# 3061MNNIC8 register map
File version: 1.0
Registers are 32-bit, access per field, reset 0x0 unless marked. A register's access mark holds for its fields unless they carry their own. Offsets are from the block's base; [hi:lo] are bit positions.

## CRC — CRC peripheral interface
Base 0x14800000
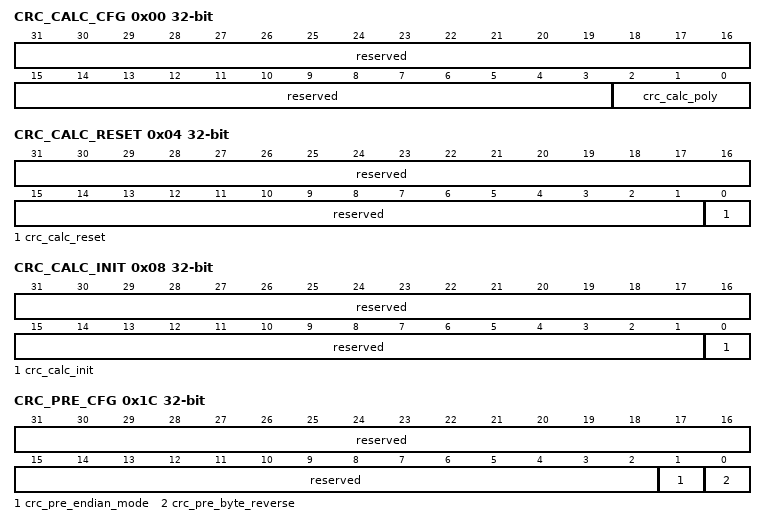
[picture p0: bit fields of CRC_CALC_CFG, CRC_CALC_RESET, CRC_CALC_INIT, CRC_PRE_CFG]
0x00 CRC_CALC_CFG — CRC计算模块，配置寄存器。
  [31:3] reserved ro — 保留。
  [2:0] crc_calc_poly rw — CRC计算模块，多项式配置： 000：CRC-8，多项式0x07； 001：保留； 010：CRC-16，多项式0x8005； 011：CRC-16，多项式0x1021； 100：CRC-32，多项式0x04c11db7； 其他：保留。
0x04 CRC_CALC_RESET — CRC计算模块软复位寄存器,复位计算，不复位配置。
  [31:1] reserved ro — 保留。
  [0] crc_calc_reset rw write-1-clears — CRC计算模块软复位，该位域写1自动清零。复位CRC计算，不复位配置。
0x08 CRC_CALC_INIT — CRC计算模块，初始化寄存器。
  [31:1] reserved ro — 保留。
  [0] crc_calc_init rw write-1-clears — CRC初始值加载信号，该位域写1自动清零，CRC计算初始化。 软件写入该位域，CRC计算初始化完成后，CRC从CRC初始值（crc_calc_init_value位域）开始计算。 注意：软件配置该位域后，再写入crc_data_in位域开始计算。
0x0C CRC_POST_XOR_VALUE rw — CRC后级处理，异或值寄存器。
  [31:0] crc_post_xor_value — CRC后级处理，异或值（XOR）。
0x10 CRC_CALC_INIT_VALUE rw — CRC计算模块，初始值寄存器。
  [31:0] crc_calc_init_value — CRC计算模块，初始值。
0x14 CRC_DATA_IN rw — CRC输入数据寄存器。
  [31:0] crc_data_in — 数据。软件写入需要计算的数据。
0x18 CRC_OUT ro — CRC结果寄存器。
  [31:0] crc_out — CRC结果，超过CRC多项式宽度的比特位是0。
0x1C CRC_PRE_CFG — CRC前级处理，配置寄存器。
  [31:2] reserved ro — 保留。
  [1] crc_pre_endian_mode rw — crc_data_in数据大小端： 0：小端； 1：大端。
  [0] crc_pre_byte_reverse rw — crc_data_in数据在字节内，按位反序（RefIn）： 0：不反序； 1：反序。
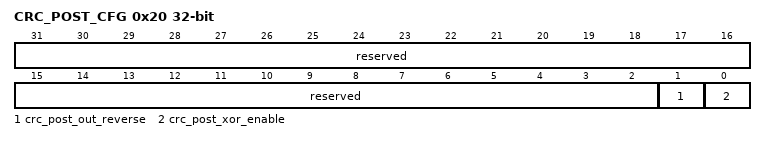
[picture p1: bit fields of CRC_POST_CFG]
0x20 CRC_POST_CFG — CRC后级处理，配置寄存器。
  [31:2] reserved ro — 保留。
  [1] crc_post_out_reverse rw — CRC结果在多项式宽度内，按位反序（RefOut）： 0：不反序； 1：反序。
  [0] crc_post_xor_enable rw — CRC结果异或（XOR）： 0：不异或； 1：异或。

## DAC — DAC peripheral interface
Base 0x18400000
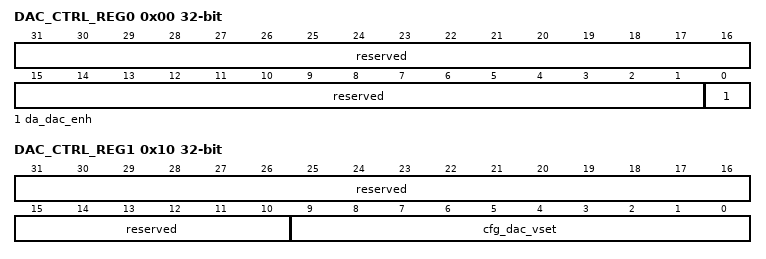
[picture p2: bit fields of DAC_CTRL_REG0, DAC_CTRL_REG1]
0x00 DAC_CTRL_REG0 — DAC控制寄存器0。
  [31:1] reserved ro — 保留。
  [0] da_dac_enh rw — DAC使能信号： 0:关闭; 1:使能。
0x10 DAC_CTRL_REG1 — DAC控制寄存器1。
  [31:10] reserved ro — 保留。
  [9:0] cfg_dac_vset rw — DAC电压档位。

## FLASH_RGN0_SHADOWS — FLASH_RGN0_SHADOWS peripheral interface
Base 0x14720000
0x00 DIE_ID_0 ro — 芯片出厂DIE_ID_0，DIE_ID寄存器。
  [31:0] die_id_0 — 芯片出厂DIE_ID_0，每颗芯片具有特异值。
0x04 DIE_ID_1 ro — 芯片出厂DIE_ID_1，DIE_ID寄存器。
  [31:0] die_id_1 — 芯片出厂DIE_ID_1，每颗芯片具有特异值。
0x10 DIE_ID_2 ro — 芯片出厂DIE_ID_2，DIE_ID寄存器。
  [31:0] die_id_2 — 芯片出厂DIE_ID_2，每颗芯片具有特异值。
0x14 DIE_ID_3 ro — 芯片出厂DIE_ID_3，DIE_ID寄存器。
  [31:0] die_id_3 — 芯片出厂DIE_ID_3，每颗芯片具有特异值。
0x20 CHIP_ID ro — 芯片出厂CHIP_ID，DIE_ID寄存器。
  [31:0] chip_id — 芯片出厂CHIP_ID，每颗芯片具有特异值。

## FLASH_RGN1_SHADOWS — FLASH_RGN1_SHADOWS peripheral interface
Base 0x14720000
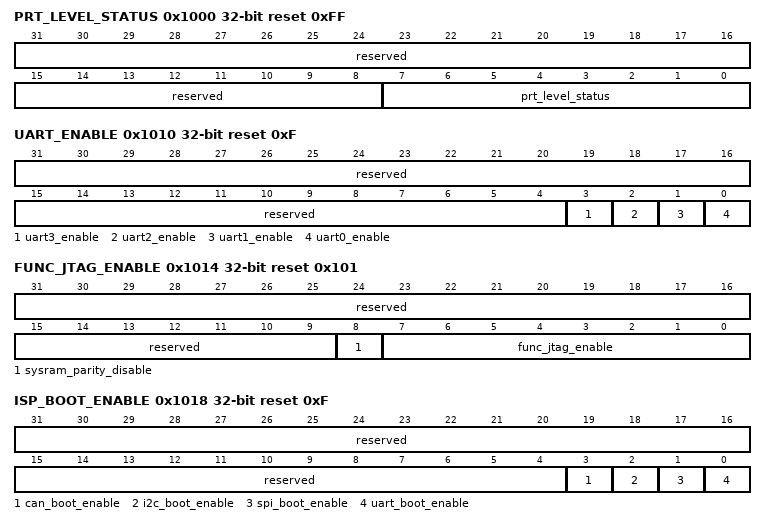
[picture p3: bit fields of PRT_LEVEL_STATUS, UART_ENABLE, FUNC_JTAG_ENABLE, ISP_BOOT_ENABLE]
0x1000 PRT_LEVEL_STATUS ro reset 0xFF — protection level管理标志。
  [31:8] reserved — 保留。
  [7:0] prt_level_status — protection level管理标志。 0xFF：JTAG/SWD接口权限开放； 其他：JTAG/SWD接口权限受限，只能访问FLASH寄存器空间，读写擦eflash main rgn1，以及读info_rgn0/1区域。 当info_rgn1处于未锁定时（info_rgn1_unlock=0xFF），protection_level支持回退机制：通过向FLASH发起回退请求，依次擦除eflash main0/1_rgn和info_rgn1，PRT_LEVEL_STATUS的值将变为0xFF。
0x1010 UART_ENABLE ro reset 0xF — UART使能标志。
  [31:4] reserved — 保留。
  [3] uart3_enable — UART3标志。 0：禁用； 1：使能。
  [2] uart2_enable — UART2能标志。 0：禁用； 1：使能。
  [1] uart1_enable — UART1使能标志。 0：禁用； 1：使能。
  [0] uart0_enable — UART0能标志。 0：禁用； 1：使能。
0x1014 FUNC_JTAG_ENABLE ro reset 0x101 — FUNC JTAG使能标志。
  [31:9] reserved — 保留。
  [8] sysram_parity_disable — SYSRAM奇偶校验使能标志。 0：使能； 1：禁用。 0：禁用； 1：使能。
  [7:0] func_jtag_enable — FUNC JTAG使能标志。 0xFF：允许； 其他：禁止。 禁止：无法通过JTAG/SWD接口访问芯片； 允许：可以通过JTAG/SWD接口访问芯片。
0x1018 ISP_BOOT_ENABLE ro reset 0xF — BOOTROM串口升级使能标志寄存器。
  [31:4] reserved — 保留。
  [3] can_boot_enable — CAN BOOT升级使能标志。 0：禁用，bootrom无法通过CAN进行串口升级； 1：使能，bootrom可以通过CAN进行串口升级。 0：禁用； 1：使能。
  [2] i2c_boot_enable — I2C BOOT升级使能标志。 0：禁用，bootrom无法通过I2C进行串口升级； 1：使能，bootrom可以通过I2C进行串口升级。
  [1] spi_boot_enable — SPI BOOT升级使能标志。 0：禁用，bootrom无法通过SPI进行升级； 1：使能，bootrom可以通过SPI进行升级。
  [0] uart_boot_enable — UART BOOT升级使能标志。 0：禁用，bootrom无法通过UART进行升级； 1：使能，bootrom可以通过UART进行升级。
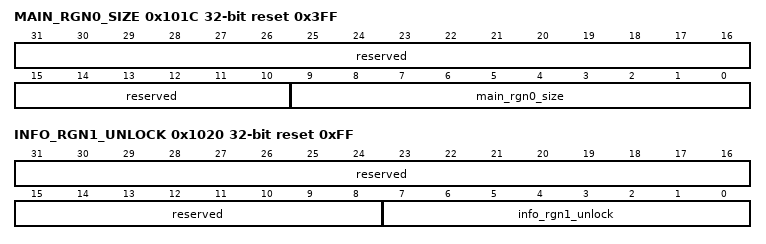
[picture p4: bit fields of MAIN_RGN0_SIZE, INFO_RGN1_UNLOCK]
0x101C MAIN_RGN0_SIZE ro reset 0x3FF — main rgn0容量大小配置寄存器。
  [31:10] reserved — 保留。
  [9:0] main_rgn0_size — main rgn0容量大小配置，单位：Page（1KB/Page）。 main rgn中小于等于main_rgn0_size的Page属于main rgn0，大于main_rgn0_size的Page属于main rgn1。
0x1020 INFO_RGN1_UNLOCK ro reset 0xFF — info_rgn1锁定标志。
  [31:8] reserved — 保留。
  [7:0] info_rgn1_unlock — info_rgn1区域锁定标志。 0xFF：未锁定； 其他：锁定。 锁定状态下，无法对info_rgn1区域进行擦除、编程操作，不支持protection level回退功能。
